# ATmega3290PA register map
Vendor: Atmel; File version: 1.0
CPU: other r0p0, little endian, no MPU, no FPU, 4 interrupt priority bits
Registers are 8-bit, read-write, reset 0x0 unless marked. A register's access mark holds for its fields unless they carry their own. Offsets are from the block's base; lines under a group give offsets from that group; [hi:lo] are bit positions; {n}, {i} and the like mark numbered series; 'fields as' and 'values as' point back to an identical list; <NAME> marks a mode.

## Memory map
0x00800000 FUSE size 0x3 — Fuses
0x00800000 LOCKBIT size 0x1 — Lockbits
0x00800020 PORTA size 0x3 — I/O Port
0x00800023 PORTB size 0x3 — I/O Port
0x00800026 PORTC size 0x3 — I/O Port
0x00800029 PORTD size 0x3 — I/O Port
0x0080002C PORTE size 0x3 — I/O Port
0x0080002F PORTF size 0x3 — I/O Port
0x00800032 PORTG size 0x3 — I/O Port
0x00800035 TC0 blocks up to offset 0x3A — Timer/Counter, 8-bit
0x00800036 TC1 blocks up to offset 0x56 — Timer/Counter, 16-bit
0x00800037 TC2 blocks up to offset 0x80 — Timer/Counter, 8-bit Async
0x0080003C EXINT blocks up to offset 0x38 — External Interrupts
0x0080003E CPU blocks up to offset 0x29 — CPU Registers
0x0080003F EEPROM size 0x4
0x0080004C SPI size 0x3 — Serial Peripheral Interface
0x00800050 AC blocks up to offset 0x30 — Analog Comparator
0x00800051 JTAG blocks up to offset 0x5 — JTAG Interface
0x00800057 BOOT_LOAD size 0x1 — Bootloader
0x00800060 WDT size 0x1 — Watchdog Timer
0x00800078 ADC blocks up to offset 0x7 — Analog-to-Digital Converter
0x008000B8 USI size 0x3 — Universal Serial Interface
0x008000C0 USART0 blocks up to offset 0x7 — USART
0x008000D8 PORTH size 0x3 — I/O Port
0x008000DB PORTJ size 0x3 — I/O Port
0x008000E4 LCD blocks up to offset 0x1C — Liquid Crystal Display

## Interrupts
0 RESET (CPU) — External Pin,Power-on Reset,Brown-out Reset,Watchdog Reset,and JTAG AVR Reset. See Datasheet.
1 INT0 (CPU) — External Interrupt Request 0
2 PCINT0 (CPU) — Pin Change Interrupt Request 0
3 PCINT1 (CPU) — Pin Change Interrupt Request 1
4 TIMER2_COMP (CPU) — Timer/Counter2 Compare Match
5 TIMER2_OVF (CPU) — Timer/Counter2 Overflow
6 TIMER1_CAPT (CPU) — Timer/Counter1 Capture Event
7 TIMER1_COMPA (CPU) — Timer/Counter1 Compare Match A
8 TIMER1_COMPB (CPU) — Timer/Counter Compare Match B
9 TIMER1_OVF (CPU) — Timer/Counter1 Overflow
10 TIMER0_COMP (CPU) — Timer/Counter0 Compare Match
11 TIMER0_OVF (CPU) — Timer/Counter0 Overflow
12 SPI_STC (CPU) — SPI Serial Transfer Complete
13 USART_RX (CPU) — USART, Rx Complete
14 USART_UDRE (CPU) — USART Data register Empty
15 USART0_TX (CPU) — USART0, Tx Complete
16 USI_START (CPU) — USI Start Condition
17 USI_OVERFLOW (CPU)
18 ANALOG_COMP (CPU) — Analog Comparator
19 ADC (CPU) — ADC Conversion Complete
20 EE_READY (CPU) — EEPROM Ready
21 SPM_READY (CPU) — Store Program Memory Read
22 LCD (CPU) — LCD Start of Frame
23 PCINT2 (CPU) — Pin Change Interrupt Request 2
24 PCINT3 (CPU) — Pin Change Interrupt Request 3

## AC — Analog Comparator
Base 0x00800050
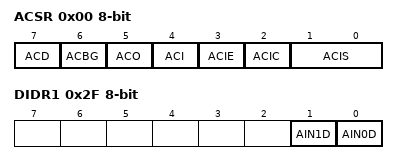
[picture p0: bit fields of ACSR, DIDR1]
0x00 ACSR — Analog Comparator Control And Status Register (read-only for debugger)
  [7] ACD — Analog Comparator Disable
  [6] ACBG — Analog Comparator Bandgap Select
  [5] ACO — Analog Compare Output
  [4] ACI — Analog Comparator Interrupt Flag
  [3] ACIE — Analog Comparator Interrupt Enable
  [2] ACIC — Analog Comparator Input Capture Enable
  [1:0] ACIS — Analog Comparator Interrupt Mode Select bits
    0=INTERRUPT_ON_TOGGLE; 2=INTERRUPT_ON_FALLING_EDGE; 3=INTERRUPT_ON_RISING_EDGE
0x2B ADCSRB — ADC Control and Status Register B
  [6] ACME — Analog Comparator Multiplexer Enable
0x2F DIDR1 — Digital Input Disable Register 1
  [1] AIN1D — AIN1 Digital Input Disable
  [0] AIN0D — AIN0 Digital Input Disable

## ADC — Analog-to-Digital Converter
Base 0x00800078
0x00 ADC 16-bit (reset mask 0xFF) — ADC Data Register Bytes
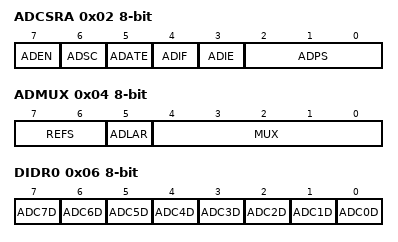
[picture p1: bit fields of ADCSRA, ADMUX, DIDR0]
0x02 ADCSRA — The ADC Control and Status register (read-only for debugger)
  [7] ADEN — ADC Enable
  [6] ADSC — ADC Start Conversion
  [5] ADATE — ADC Auto Trigger Enable
  [4] ADIF — ADC Interrupt Flag
  [3] ADIE — ADC Interrupt Enable
  [2:0] ADPS — ADC Prescaler Select Bits
    1=2; 2=4; 3=8; 4=16; 5=32; 6=64; 7=128
0x03 ADCSRB — ADC Control and Status Register B
  [2:0] ADTS — ADC Auto Trigger Sources
0x04 ADMUX — The ADC multiplexer Selection Register
  [7:6] REFS — Reference Selection Bits
    0=AREF_INTERNAL_VREF_TURNED_OFF; 1=AVCC_WITH_EXTERNAL_CAPACITOR_AT_AREF_PIN; 3=INTERNAL_1_1V_VOLTAGE_REFERENCE_WITH_EXTERNAL_CAPACITOR_AT_AREF_PIN
  [5] ADLAR — Left Adjust Result
  [4:0] MUX — Analog Channel and Gain Selection Bits
0x06 DIDR0 — Digital Input Disable Register 0
  [n] ADC{n}D (n=0..7) — ADC{n} Digital input Disable
